# ET6801 register map
Vendor: ETMCU Inc.; File version: v0.0.1
CPU: CM7 r2p1, little endian, MPU, FPU, I-cache, D-cache, ITCM, DTCM, 4 interrupt priority bits
Registers are 32-bit, read-write, reset 0x0 unless marked. A register's access mark holds for its fields unless they carry their own. Offsets are from the block's base; [hi:lo] are bit positions.

## FMAC — Provide an overview of the purpose and functionality of the peripheral: fmac_cfg
Base 0x40204000
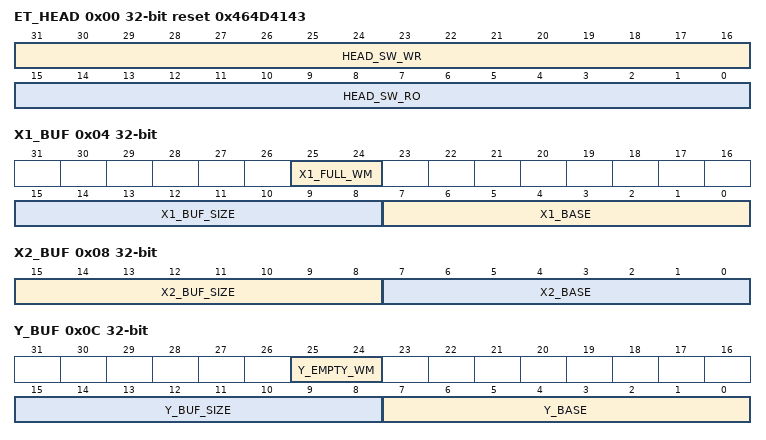
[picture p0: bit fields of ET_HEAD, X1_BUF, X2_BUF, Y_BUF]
0x00 ET_HEAD reset 0x464D4143
  [31:16] HEAD_SW_WR — 软件测试读写寄存器，硬件无访问，静态寄存器
  [15:0] HEAD_SW_RO ro — 软件只读上报寄存器，硬件无访问,FMAC的ASCII 码表示，静态寄存器
0x04 X1_BUF
  [25:24] X1_FULL_WM — watermark for buffer full flag，准静态寄存器 在循环模式下定义X1缓冲区满标志位的阈值。如果缓冲区中的空闲空间数量小于2^full_wm，则设置该标志。 'd0:阈值= 1 'd1:阈值= 2 'd2:阈值= 4 'd3:阈值= 8 设置大于1的阈值允许在一个中断下将多个数据传输到缓冲区(数据通过ahb总线先写入到wdata寄存器，然后再从wdata寄存器写入到缓冲区中)。 如果启用DMA写请求，阈值应设置为1 (dmawen在CR寄存器中= 1)。
  [15:8] X1_BUF_SIZE — x1缓冲区的分配大小(16 bits) ，准静态寄存器 最小缓冲区大小是滤波器中前馈抽头的数量(+阈值- 1)。
  [7:0] X1_BASE — x1缓冲区的基址，准静态寄存器
0x08 X2_BUF
  [15:8] X2_BUF_SIZE — x2缓冲区大小，单位16bits，准静态寄存器 当功能正在执行(enable = 1)时，不能修改此位域。
  [7:0] X2_BASE — x2缓冲区的基址，动态寄存器 可以在enable=1时修改x2缓冲区基址，例如更改系数值。这样做时，滤波器应该暂停，因为在计算进行时改变系数会影响结果。
0x0C Y_BUF
  [25:24] Y_EMPTY_WM — watermark for buffer empty flag，准静态寄存器 在循环模式下，Y缓冲区空标志的阈值。如果缓冲区中未读值的数量小于2^empty_wm，则设置该标志。 'd0:阈值= 1 'd1:阈值= 2 'd2:阈值= 4 'd3:阈值= 8 设置大于1的阈值允许在一个中断下从缓冲区传输多个数据。 如果DMA读请求被启用，阈值应该设置为1(在CR寄存器中dmaren = 1)。
  [15:8] Y_BUF_SIZE — y缓冲区大小，单位16bits，准静态寄存器 对于FIR滤波器，最小缓冲区大小为1(+阈值)。对于IIR滤波器，最小缓冲区大小是反馈抽头的数量(+阈值)。
  [7:0] Y_BASE — y缓冲区的基址，准静态寄存器
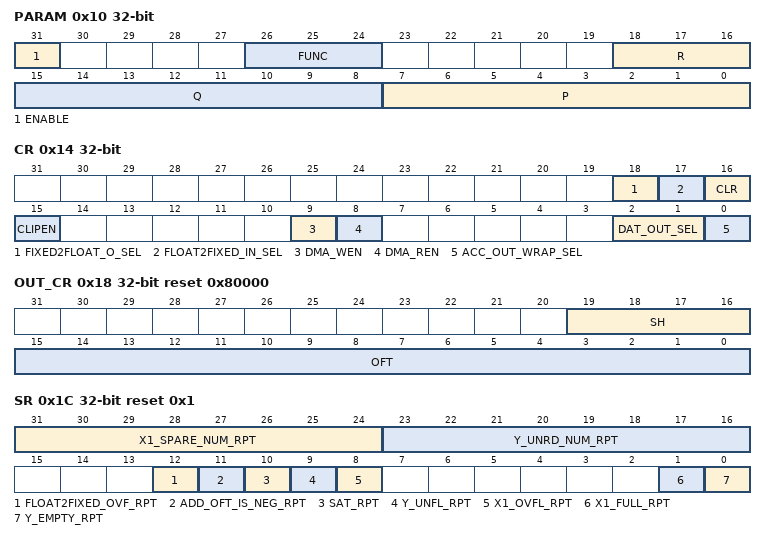
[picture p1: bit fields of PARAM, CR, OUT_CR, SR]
0x10 PARAM
  [31] ENABLE — 启动执行，动态寄存器 'd0:停止执行 'd1:开始执行 设置此位将触发func位域中所选函数的执行。通过软件拉低将停止任何正在进行的功能。对于初始化功能，该位由硬件拉低。
  [26:24] FUNC — 功能模式，准静态寄存器 'd1:装入X1缓冲区（P包含要加载到X1缓冲区中的值的数量） 'd2:加载X2缓冲区（P包含要从地址X2_BASE开始加载到X2缓冲区中的值的数量，Q包含要从地址X2_BASE + P开始加载到X2缓冲区中的值的数量） 'd3:加载Y缓冲区（P包含要加载到Y缓冲区中的值的数量） 'd4:卷积(FIR滤波器，和P参数有关，此时P参数表示fir系数的个数) 'd5: IIR滤波器(直接形式1，和p，q参数有关，此时p参数表示iir前馈通路系数的个数，q表示iir反馈通路的个数) other:保留,没有功能被启动 当功能正在运行时，不能修改此位域(enable = 1)
  [18:16] R — 输入参数r，准静态寄存器。 该参数的值与功能有关。 当功能正在运行时，不能修改此位域(enable = 1)
  [15:8] Q — 输入参数q，准静态寄存器。 该参数的值与功能有关。 当功能正在运行时，不能修改此位域(enable = 1)
  [7:0] P — 输入参数p，准静态寄存器。 该参数的值与功能有关。 当功能正在运行时，不能修改此位域(enable = 1)
0x14 CR
  [18] FIXED2FLOAT_O_SEL — 输出数据定点数转单精度浮点数选择 'd0:输出数据为16bit定点数<s(16,15)>，不需要转换。 'd1:数出数据为32bit单精度浮点数，需要将16bit定点数<s(16,15)>进行转换。
  [17] FLOAT2FIXED_IN_SEL — 输入数据单精度浮点数转定点数选择 'd0:输入数据为16bit定点数<s(16,15)>，不需要转换。 'd1:数据数据为32bit单精度浮点数，需要转换为16bit定点数<s(16,15)>。
  [16] CLR — 软件清零寄存器，动态寄存器 这将重置写入和读取指针，内部控制逻辑，SR寄存器和PARAM寄存器的cfg_enable位域。其他寄存器设置则不受到影响。此位由硬件复位。 'd0: 复位无效 'd1:复位激活 该位由软件设置和清除。
  [15] CLIPEN — clipen:启用修剪，准静态寄存器 'd0:关闭修剪。累加器结果超过s(26,22)范围的值将wrap。 'd1:启用修剪。超过s(26,22)范围的累加器输出的值，根据符号饱和到最大正负值(+((2^25-1)/ 2^25) 或 -1)。
  [9] DMA_WEN — dmawen:使能DMA写通道请求，准静态寄存器 'd0:禁用。没有DMA请求 'd1:启用。在x1缓冲区未满时生成DMA请求。 这个位只能在PARAM寄存器中的enable= 0时被修改。读取返回该位的当前状态。
  [8] DMA_REN — dmaren:启用DMA读通道请求，准静态寄存器 'd0:禁用。没有DMA请求 'd1:启用。在Y缓冲区不为空时生成DMA请求。 这个位只能在PARAM寄存器中的enable= 0时被修改。读取返回该位的当前状态。
  [2:1] DAT_OUT_SEL — fmac输出数据选择 'd0:不做任何处理，将memory的运算结果直接输出； 'd1:将memory的运算结果加上偏移量之后，饱和截尾到12bit有效位输出。 'd2:将memory的运算结果加上偏移量之后，饱和截尾到16bit有效位输出。
  [0] ACC_OUT_WRAP_SEL — 累加器的输出是否做wrap 'd0:累加器的输出不做wrap，做saturate，超过s(16,15)范围的累加器输出的值，根据符号饱和到最大正负值(+((2^15-1)/ 2^15) 或 -1)。 'd1: 累加器的输出做wrap。累加器结果超过s(16,15)范围的值将wrap。
0x18 OUT_CR reset 0x80000
  [19:16] SH — fmac输出加上偏移量之后的移位选择 'd0:左移8位； 'd1:左移7位； ...... 'd7:左移1位； 'd8:不移位； 'd9:右移1位； ...... 'd15:右移7位；
  [15:0] OFT — fmac输出数据偏移量
0x1C SR reset 0x1
  [31:24] X1_SPARE_NUM_RPT ro — x1 buffer空闲空间的数量，动态寄存器
  [23:16] Y_UNRD_NUM_RPT ro — y buffer中未读数据的数量，动态寄存器
  [12] FLOAT2FIXED_OVF_RPT — 输入单精度浮点数转定点数溢出上报信号 'd0:未溢出，或者之前发生过溢出，已被软件清除 'd1: 之前发生溢出并且未被软件清除 当输入浮点数大于定点数表示值的范围时产生，此时定点数的输出将被钳位在最大值；当输入浮点数小于定点数表示值的范围时产生，此时定点数的输出将被钳位在最小值；
  [11] ADD_OFT_IS_NEG_RPT — 累加器的输出加上偏移量之后仍为负数，软件写1清，动态寄存器 'd0:累加器输出加偏移量之后不为负数 'd1: 累加器输出加偏移量之后仍为负数
  [10] SAT_RPT ro — 饱和误差标志，动态寄存器 当累加的结果超过累加器的数值范围时，就会发生饱和。 'd0:表示不饱和 'd1:饱和检测。
  [9] Y_UNFL_RPT ro — 下溢错误标志，动态寄存器 当y缓冲区中没有有效数据时，从RDATA进行读操作，就会发生下溢。 'd0:表示未检测到下溢 'd1:检测到下溢。如果设置了unflien位，则会产生中断。 重置单元可以清除该标志。
  [8] X1_OVFL_RPT ro — 溢出错误标志，动态寄存器 当x1缓冲区中没有可用的空闲空间时，对WDATA进行写操作，就会发生溢出。 'd0:表示没有溢出 'd1:溢出检测。如果设置了ovflien位，则会生成中断。 重置单元可以清除该标志。
  [1] X1_FULL_RPT ro — x1缓冲区满标志，动态寄存器 如果可用空间数量小于full_wm阈值，则缓冲区被标记为已满。可用空间数是写指针与当前正在使用的最近采样之间的差值。 'd0: x1缓冲区未满。如果设置了wien位，中断请求将被断言，直到该标志被设置为止。如果设置了dmawen，则会生成DMA写通道请求，直到设置该标志为止。 'd1: x1缓冲区已满。 该标志由硬件或复位设置和清除。 注意:在X1缓冲区的最后一个可用空间被填满后，在x1full标志变高之前有3个时钟周期的延迟。为了避免任何溢出的风险，建议在写入x1缓冲区后在读取SR之前插入软件延迟。或者，也可以使用full_wm阈值2。
  [0] Y_EMPTY_RPT ro — y缓冲区空标志，动态寄存器 如果未读数据数量小于empty_wm阈值，缓冲区将被标记为空。未读数据数是读指针与当前输出目的地址之差。 'd0: Y缓冲区不空。如果设置了rien位，中断请求将被断言，直到该标志被设置为止。如果设置了dmaren，则会生成DMA读通道请求，直到设置该标志为止。 'd1: Y缓冲区为空。 该标志由硬件或复位设置和清除。
0x20 FIFO_DATA
  [31:0] FIFO_DATA — 这个寄存器的操作行为对应内部的memory,操作memory的读写使能和读写数据，memory的地址由内部产生
0x24 INT_EN
  [10:0] INT_EN — 动态寄存器 bit10: 'd0:关闭load y buffer写入错误中断; 'd1:使能load y buffer写入错误中断; bit9: 'd0:关闭load x2 buffer写入错误中断; 'd1:使能load x2 buffer写入错误中断; bit8: 'd0:关闭load x1 buffer写入错误中断; 'd1:使能load x1 buffer写入错误中断; bit7: 'd0:关闭软件配置q参数错误中断; 'd1:使能软件配置q参数错误中断; bit6: 'd0:关闭软件配置pq参数错误中断; 'd1:使能软件配置pq参数错误中断; bit5: 'd0:关闭软件配置p参数错误中断; 'd1:使能软件配置p参数错误中断; bit4: 'd0:关闭y buffer下溢中断; 'd1:使能y buffer下溢中断; bit3: 'd0:关闭x1 buffer上溢中断; 'd1:使能x1 buffer上溢中断; bit2: 'd0:关闭fir/iir运算饱和中断; 'd1:使能fir/iir运算饱和中断; bit1: 'd0:关闭y buffer读请求中断; 'd1:使能y buffer读请求中断; bit0: 'd0:关闭x1 buffer写请求中断; 'd1:使能x1 buffer写请求中断;
0x28 INT_MASK
  [10:0] INT_MASK — 动态寄存器 bit10: 'd0: 取消屏蔽load y buffer写入错误中断; 'd1: 屏蔽load y buffer写入错误中断; bit9: 'd0: 取消屏蔽load x2 buffer写入错误中断; 'd1: 屏蔽load x2 buffer写入错误中断; bit8: 'd0: 取消屏蔽load x1 buffer写入错误中断; 'd1: 屏蔽load x1 buffer写入错误中断; bit7: 'd0: 取消屏蔽软件配置q参数错误中断; 'd1: 屏蔽软件配置q参数错误中断; bit6: 'd0: 取消屏蔽软件配置pq参数错误中断; 'd1: 屏蔽软件配置pq参数错误中断; bit5: 'd0: 取消屏蔽软件配置p参数错误中断; 'd1: 屏蔽软件配置p参数错误中断; bit4: 'd0:取消屏蔽y buffer下溢中断; 'd1:屏蔽y buffer下溢中断; bit3: 'd0:取消屏蔽x1 buffer上溢中断; 'd1:屏蔽x1 buffer上溢中断; bit2: 'd0:取消屏蔽fir/iir运算饱和中断; 'd1:屏蔽fir/iir运算饱和中断; bit1: 'd0:取消屏蔽y buffer读请求中断; 'd1:屏蔽y buffer读请求中断; bit0: 'd0:取消屏蔽x1 buffer写请求中断; 'd1:屏蔽x1 buffer写请求中断;
0x2C INT_FORCE_IND
  [10:0] INT_FORCE_IND — 动态寄存器 1表示强制产生相应的测试中断，硬件自清零
0x30 INT_CLR
  [10:0] INT_CLR — 动态寄存器 1表示清除相应的中断状态，硬件自清零
0x34 INT_RAW_RPT ro
  [10:0] INT_RAW_RPT — 动态寄存器，中断MASK前RAW 中断状态上报
0x38 INT_STATUS_RPT ro
  [10:0] INT_STATUS_RPT — 动态寄存器，中断MASK后中断状态上报
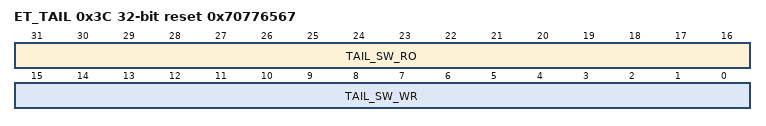
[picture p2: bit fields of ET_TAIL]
0x3C ET_TAIL reset 0x70776567
  [31:16] TAIL_SW_RO ro — 软件只读硬件上报寄存器，静态寄存器
  [15:0] TAIL_SW_WR — 软件测试读写寄存器，硬件无访问，静态寄存器
